# STM32F030C6T6 register map
File version: 1.0
Registers are 32-bit, access not given, reset 0x0 unless marked. A register's access mark holds for its fields unless they carry their own. Offsets are from the block's base; [hi:lo] are bit positions; {n}, {i} and the like mark numbered series; 'fields as' and 'values as' point back to an identical list.

## TIM15
Base 0x40014000
0x00 CR1
  [9:8] CKD, [7] ARPE, [31:4] s, [3] OPM, [2] URS, [1] UDIS, [0] CEN
0x04 CR2
  [10] OIS2, [9] OIS1N, [8] OIS1, [6:4] MMS, [3] CCDS, [2] CCUS, [31:1] s, [0] CCPC
0x08 SMCR
  [7] MSM, [6:4] TS, [31:3] s, [2:0] SMS
0x0C DIER
  [14] TDE, [10] CC2DE, [9] CC1DE, [8] UDE, [7] BIE, [6] TIE, [5] COMIE, [31:3] s, [2] CC2IE, [1] CC1IE, [0] UIE
0x10 SR
  [10] CC2OF, [9] CC1OF, [7] BIF, [6] TIF, [5] COMIF, [31:3] s, [2] CC2IF, [1] CC1IF, [0] UIF
0x14 EGR
  [7] BG, [6] TG, [5] COMG, [31:3] s, [2] CC2G, [1] CC1G, [0] UG
0x18 CCMR1_OUT
  [14:12] OC2M, [11] OC2PE, [10] OC2FE, [9:8] CC2S, [31:7] s, [6:4] OC1M, [3] OC1PE, [2] OC1FE, [1:0] CC1S
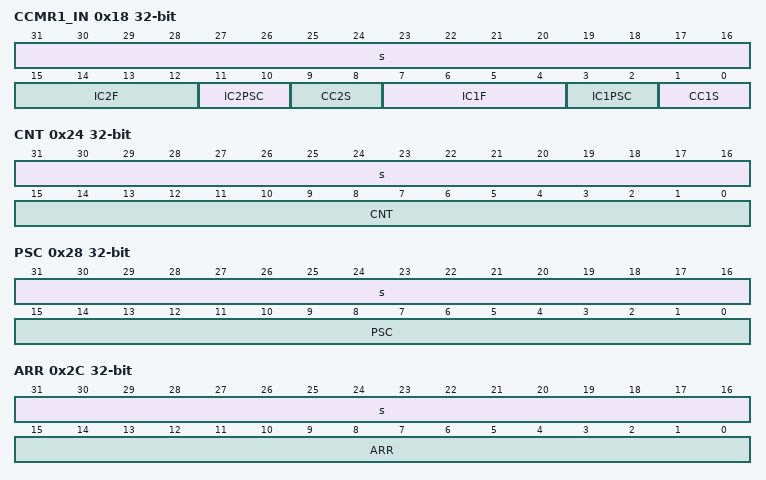
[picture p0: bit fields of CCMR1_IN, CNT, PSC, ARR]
0x18 CCMR1_IN
  [31:16] s, [15:12] IC2F, [11:10] IC2PSC, [9:8] CC2S, [7:4] IC1F, [3:2] IC1PSC, [1:0] CC1S
0x20 CCER
  [7] CC2NP, [31:6] s, [5] CC2P, [4] CC2E, [3] CC1NP, [2] CC1NE, [1] CC1P, [0] CC1E
0x24 CNT
  [31:16] s, [15:0] CNT
0x28 PSC
  [31:16] s, [15:0] PSC
0x2C ARR
  [31:16] s, [15:0] ARR
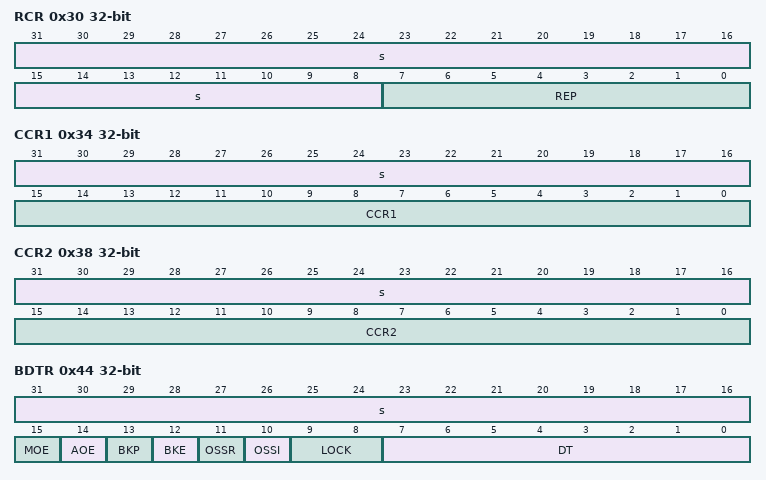
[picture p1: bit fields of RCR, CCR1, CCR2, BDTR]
0x30 RCR
  [31:8] s, [7:0] REP
0x34 CCR1
  [31:16] s, [15:0] CCR1
0x38 CCR2
  [31:16] s, [15:0] CCR2
0x44 BDTR
  [31:16] s, [15] MOE, [14] AOE, [13] BKP, [12] BKE, [11] OSSR, [10] OSSI, [9:8] LOCK, [7:0] DT
0x48 DCR
  [12:8] DBL, [31:5] s, [4:0] DBA
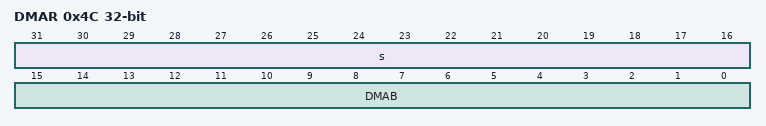
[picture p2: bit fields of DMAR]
0x4C DMAR
  [31:16] s, [15:0] DMAB

## TIM16
Base 0x40014400
Same registers: TIM17 0x40014800
Registers as TIM15, without SMCR, CCMR1_OUT, CCMR1_IN, CCR2; these are added or differ:
0x04 CR2
  [9] OIS1N, [8] OIS1, [3] CCDS, [2] CCUS, [31:1] s, [0] CCPC
0x0C DIER
  [9] CC1DE, [8] UDE, [7] BIE, [5] COMIE, [31:2] s, [1] CC1IE, [0] UIE
0x10 SR
  [9] CC1OF, [7] BIF, [5] COMIF, [31:2] s, [1] CC1IF, [0] UIF
0x14 EGR
  [7] BG, [5] COMG, [31:2] s, [1] CC1G, [0] UG
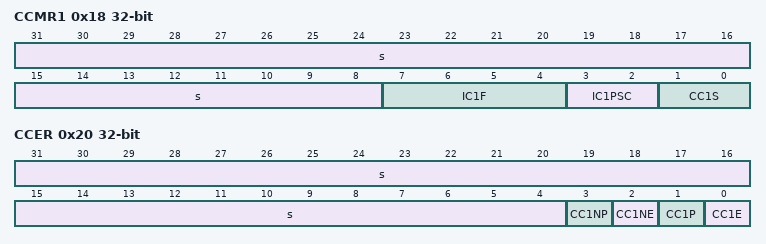
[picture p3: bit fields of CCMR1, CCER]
0x18 CCMR1
  [31:8] s, [7:4] IC1F, [3:2] IC1PSC, [1:0] CC1S
0x20 CCER
  [31:4] s, [3] CC1NP, [2] CC1NE, [1] CC1P, [0] CC1E

## DMA
Base 0x40020000
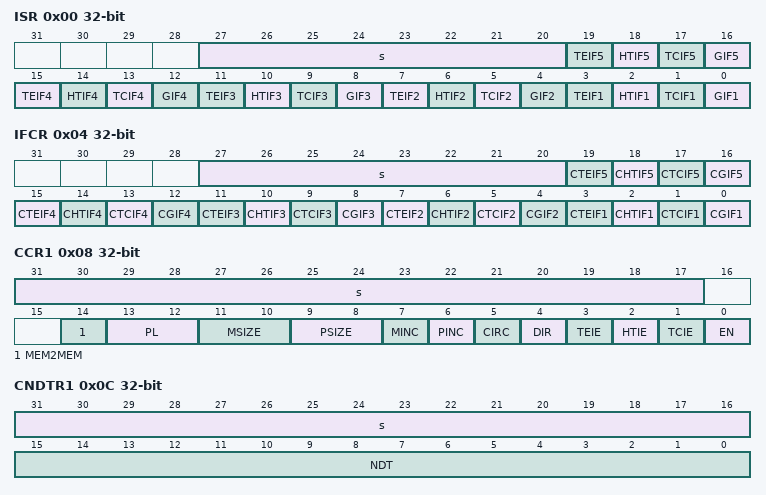
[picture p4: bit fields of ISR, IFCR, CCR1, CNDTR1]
0x00 ISR
  [27:20] s, [4n-1] TEIF{n} (n=1..5), [4n-2] HTIF{n} (n=1..5), [4n-3] TCIF{n} (n=1..5), [4n-4] GIF{n} (n=1..5)
0x04 IFCR
  [27:20] s, [4n-1] CTEIF{n} (n=1..5), [4n-2] CHTIF{n} (n=1..5), [4n-3] CTCIF{n} (n=1..5), [4n-4] CGIF{n} (n=1..5)
0x08 CCR1
  [31:17] s, [14] MEM2MEM, [13:12] PL, [11:10] MSIZE, [9:8] PSIZE, [7] MINC, [6] PINC, [5] CIRC, [4] DIR, [3] TEIE, [2] HTIE, [1] TCIE, [0] EN
0x0C CNDTR1
  [31:16] s, [15:0] NDT
0x10 CPAR1
  [31:0] PA
{0x0+0x14*i} CMAR{i} (i=1..5)
  [31:0] MA
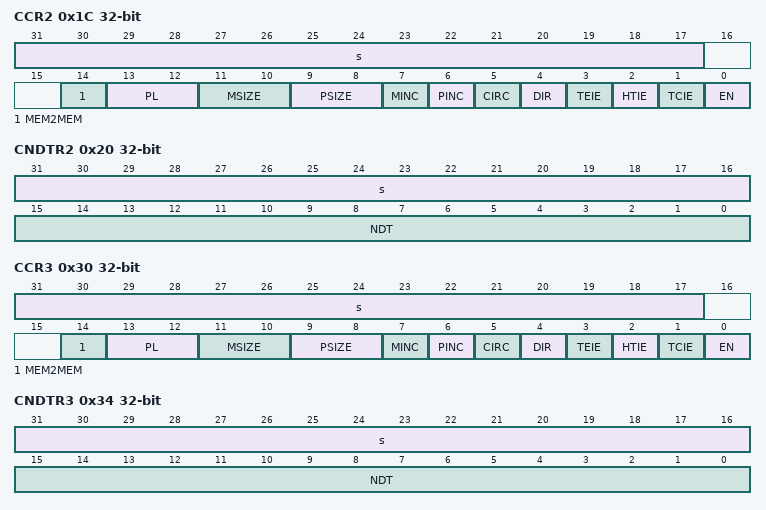
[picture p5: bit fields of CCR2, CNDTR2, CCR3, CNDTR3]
0x1C CCR2
  fields as CCR1
0x20 CNDTR2
  [31:16] s, [15:0] NDT
0x24 CPAR2
  [31:0] PA
0x30 CCR3
  fields as CCR1
0x34 CNDTR3
  [31:16] s, [15:0] NDT
0x38 CPAR3
  [31:0] PA
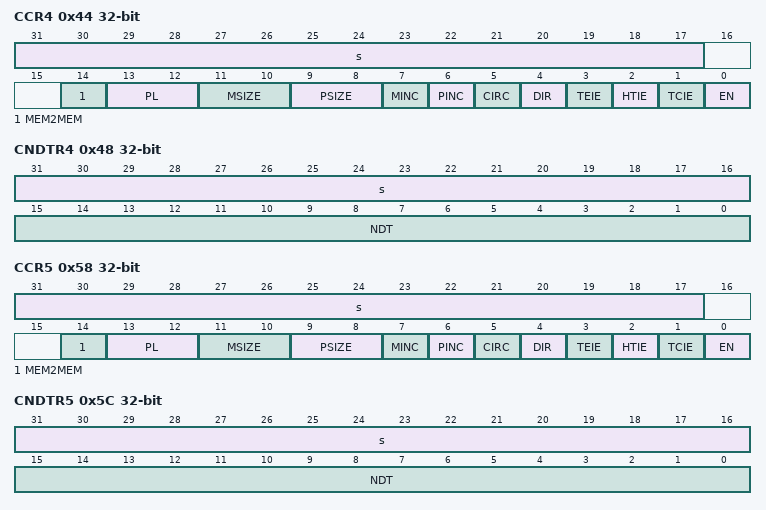
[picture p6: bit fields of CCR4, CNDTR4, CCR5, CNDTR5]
0x44 CCR4
  fields as CCR1
0x48 CNDTR4
  [31:16] s, [15:0] NDT
0x4C CPAR4
  [31:0] PA
0x58 CCR5
  fields as CCR1
0x5C CNDTR5
  [31:16] s, [15:0] NDT
0x60 CPAR5
  [31:0] PA

## RCC
Base 0x40021000
0x00 CR
  [25] PLLRDY, [24] PLLON, [19] CSSON, [18] HSEBYP, [17] HSERDY, [16] HSEON, [15:8] HSICAL, [7:3] HSITRIM, [31:2] s, [1] HSIRDY, [0] HSION
0x04 CFGR
  [31] PLLNODIV, [30:28] MCOPRE, [27:24] MCO, [21:18] PLLMUL, [17] PLLXTPRE, [16] PLLSRC, [14] ADCPRE, [23:11] s, [10:8] PPRE, [7:4] HPRE, [3:2] SWS, [1:0] SW
0x08 CIR
  [23] CSSC, [21] HSI14RDYC, [20] PLLRDYC, [19] HSERDYC, [18] HSIRDYC, [17] LSERDYC, [16] LSIRDYC, [13] HSI14RDYIE, [12] PLLRDYIE, [11] HSERDYIE, [10] HSIRDYIE, [9] LSERDYIE, [8] LSIRDYIE, [7] CSSF, [31:6] s, [5] HSI14RDYF, [4] PLLRDYF, [3] HSERDYF, [2] HSIRDYF, [1] LSERDYF, [0] LSIRDYF
0x0C APB2RSTR
  [22] DBGMCURST, [18] TIM17RST, [17] TIM16RST, [16] TIM15RST, [14] USART1RST, [12] SPI1RST, [11] TIM1RST, [9] ADCRST, [6] USART6RST, [31:1] s, [0] SYSCFGRST
0x10 APB1RSTR
  [28] PWRRST, [27] CRSRST, [23] USBRST, [22] I2C2RST, [21] I2C1RST, [n+15] USART{n}RST (n=2..5), [14] SPI2RST, [11] WWDGRST, [8] TIM14RST, [5] TM7RST, [4] TM6RST, [1] TIM3RST, [31:0] s
0x14 AHBENR
  [21] IOPEEN, [20] USART4RST, [19] IOPCEN, [18] IOPBEN, [17] IOPAEN, [6] CRCEN, [4] FLITFEN, [2] SRAMEN, [31:1] s, [0] DMAEN
0x18 APB2ENR
  [22] DBGMCUEN, [18] TIM17EN, [17] TIM16EN, [16] TIM15EN, [14] USART1EN, [12] SPI1EN, [11] TIM1EN, [9] ADCEN, [5] USART6EN, [31:1] s, [0] SYSCFGEN
0x1C APB1ENR
  [28] PWREN, [27] CRSEN, [23] USBEN, [22] I2C2EN, [21] I2C1EN, [n+15] USART{n}EN (n=2..5), [14] SPI2EN, [11] WWDGEN, [8] TIM14EN, [5] TIM7EN, [4] TIM6EN, [1] TIM3EN, [31:0] s
0x20 BDCR
  [16] BDRST, [15] RTCEN, [9:8] RTCSEL, [31:5] s, [4:3] LSEDRV, [2] LSEBYP, [1] LSERDY, [0] LSEON
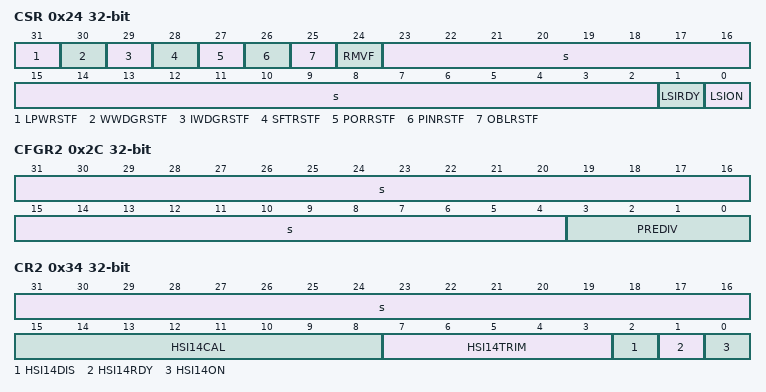
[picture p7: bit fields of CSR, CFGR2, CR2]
0x24 CSR
  [31] LPWRSTF, [30] WWDGRSTF, [29] IWDGRSTF, [28] SFTRSTF, [27] PORRSTF, [26] PINRSTF, [25] OBLRSTF, [24] RMVF, [23:2] s, [1] LSIRDY, [0] LSION
0x28 AHBRSTR
  [22] IOPFRST, [20] IOPDRST, [19] IOPCRST, [18] IOPBRST, [17] IOPARST, [31:0] s
0x2C CFGR2
  [31:4] s, [3:0] PREDIV
0x30 CFGR3
  [8] ADCSW, [7] USBSW, [4] I2C1SW, [31:2] s, [1:0] USART1SW
0x34 CR2
  [31:16] s, [15:8] HSI14CAL, [7:3] HSI14TRIM, [2] HSI14DIS, [1] HSI14RDY, [0] HSI14ON

## FLASH
Base 0x40022000
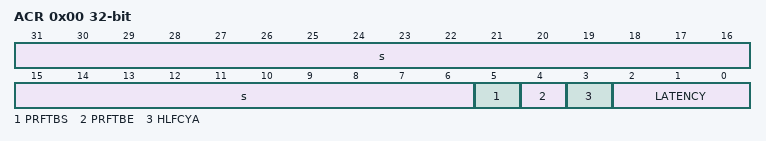
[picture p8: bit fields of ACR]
0x00 ACR
  [31:6] s, [5] PRFTBS, [4] PRFTBE, [3] HLFCYA, [2:0] LATENCY
0x04 KEYR
  [31:0] FKEY
0x08 OPTKEYR
  [31:0] OPTKEY
0x0C SR
  [5] EOP, [4] WRPRTERR, [31:3] s, [2] PGERR, [1] ERLYBSY, [0] BSY
0x10 CR
  [13] OBL_LAUNCH, [12] EOPIE, [10] ERRIE, [9] OPTWRE, [7] LOCK, [6] STRT, [5] OPTER, [4] OPTPG, [31:3] s, [2] MER, [1] PER, [0] PG
0x14 AR
  [31:0] FAR
0x1C OBR
  [31:24] Data1, [23:16] Data0, [14] RAM_PARITY_CHECK, [13] VDDA_MONITOR, [12] nBOOT1, [10] nRST_STDBY, [9] nRST_STOP, [8] WDG_SW, [15:3] s, [2:1] RDPRT, [0] OPTERR
0x20 WRPR
  [31:0] WRP

## CRC
Base 0x40023000
0x00 DR
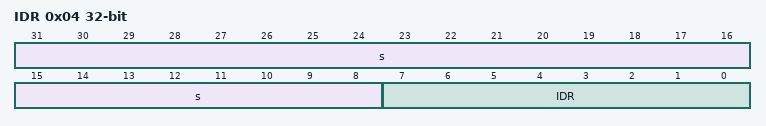
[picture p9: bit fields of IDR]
0x04 IDR
  [31:8] s, [7:0] IDR
0x08 CR
  [7] REV_OUT, [6:5] REV_IN, [31:1] s, [0] RESET
0x10 INIT
  [31:0] CRC_INIT

## GPIOA
Base 0x48000000
Same registers: GPIOB 0x48000400, GPIOC 0x48000800, GPIOD 0x48000C00, GPIOF 0x48001400
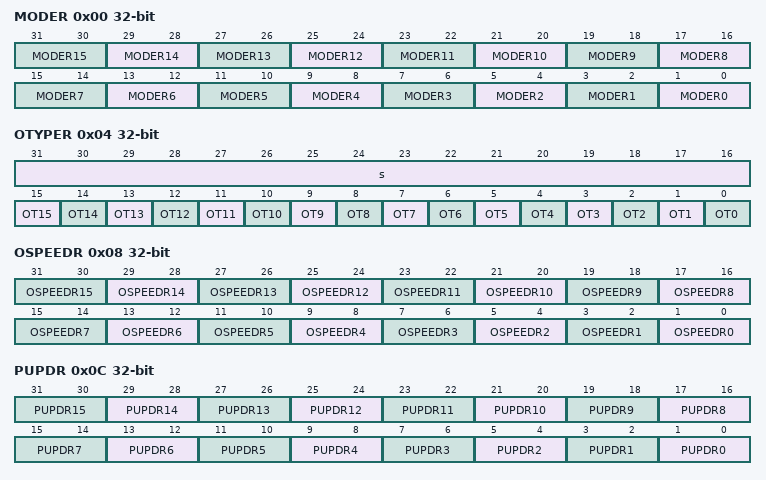
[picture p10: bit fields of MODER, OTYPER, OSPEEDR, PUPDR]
0x00 MODER
  [2n+1:2n] MODER{n} (n=0..15)
0x04 OTYPER
  [31:16] s, [n] OT{n} (n=0..15)
0x08 OSPEEDR
  [2n+1:2n] OSPEEDR{n} (n=0..15)
0x0C PUPDR
  [2n+1:2n] PUPDR{n} (n=0..15)
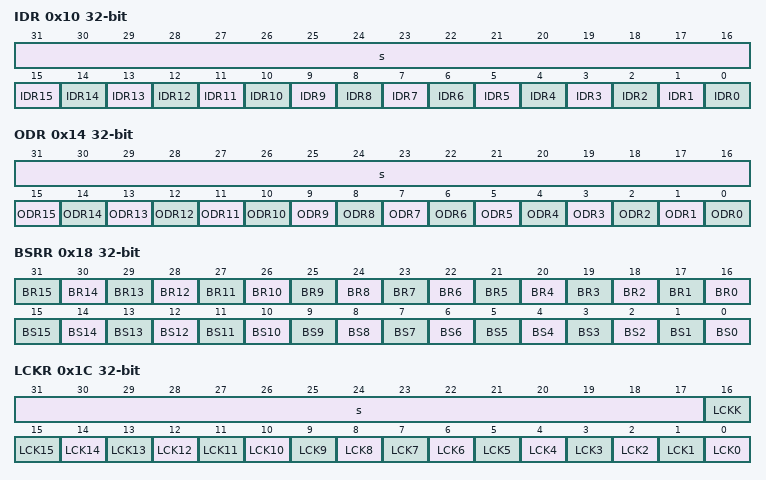
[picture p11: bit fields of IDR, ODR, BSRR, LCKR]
0x10 IDR
  [31:16] s, [n] IDR{n} (n=0..15)
0x14 ODR
  [31:16] s, [n] ODR{n} (n=0..15)
0x18 BSRR
  [n+16] BR{n} (n=0..15), [n] BS{n} (n=0..15)
0x1C LCKR
  [31:17] s, [16] LCKK, [n] LCK{n} (n=0..15)
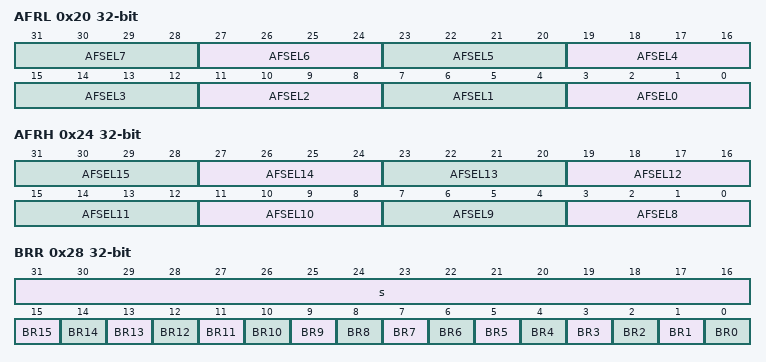
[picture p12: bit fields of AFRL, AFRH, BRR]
0x20 AFRL
  [4n+3:4n] AFSEL{n} (n=0..7)
0x24 AFRH
  [4n-29:4n-32] AFSEL{n} (n=8..15)
0x28 BRR
  [31:16] s, [n] BR{n} (n=0..15)
